AUTOSAR XML (schema 00045)
package /Comco
  client server interface CSI_NMWakupFlag
    operation NMWakupFlag: fire-and-forget=false, possible-error=[CSI_NMWakupFlag/E_NOT_OK, CSI_NMWakupFlag/E_OK]
      arg u_WakeupFlag: type=uint8_t, direction=OUT, server-argument-impl-policy=USE-ARGUMENT-TYPE
    error E_OK: error-code=0
    error E_NOT_OK: error-code=1
  client server interface CSI_nmCurrentState
    operation nmCurrentState: fire-and-forget=false, possible-error=[CSI_nmCurrentState/E_NOT_OK, CSI_nmCurrentState/E_OK]
      arg u_CurNmState: type=uint8_t, direction=OUT, server-argument-impl-policy=USE-ARGUMENT-TYPE
    error E_NOT_OK: error-code=1
    error E_OK: error-code=0
  client server interface CSI_nmPreviousState
    operation nmPreviousState: fire-and-forget=false, possible-error=[CSI_nmPreviousState/E_NOT_OK, CSI_nmPreviousState/E_OK]
      arg u_PreNmState: type=uint8_t, direction=OUT, server-argument-impl-policy=USE-ARGUMENT-TYPE
    error E_NOT_OK: error-code=1
    error E_OK: error-code=0
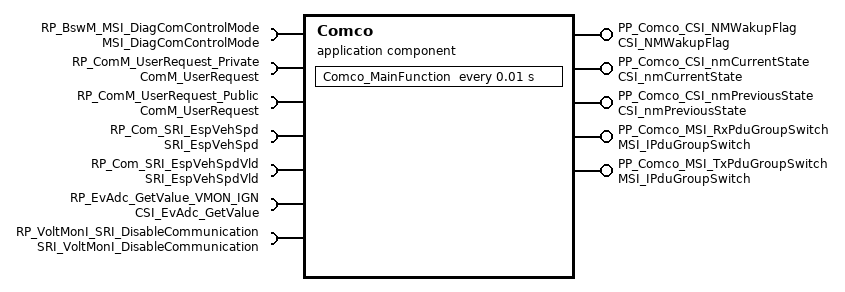
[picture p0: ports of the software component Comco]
  application sw component type Comco  # Communication Coordinator
    5 x provide port:
      PP_Comco_CSI_NMWakupFlag: provided-interface=CSI_NMWakupFlag
      PP_Comco_CSI_nmCurrentState: provided-interface=CSI_nmCurrentState
      PP_Comco_CSI_nmPreviousState: provided-interface=CSI_nmPreviousState
      PP_Comco_MSI_RxPduGroupSwitch: provided-interface=MSI_IPduGroupSwitch
      PP_Comco_MSI_TxPduGroupSwitch: provided-interface=MSI_IPduGroupSwitch
    7 x require port:
      RP_BswM_MSI_DiagComControlMode: required-interface=MSI_DiagComControlMode
      RP_ComM_UserRequest_Private: required-interface=ComM_UserRequest
      RP_ComM_UserRequest_Public: required-interface=ComM_UserRequest
      RP_Com_SRI_EspVehSpd: required-interface=SRI_EspVehSpd
      RP_Com_SRI_EspVehSpdVld: required-interface=SRI_EspVehSpdVld
      RP_EvAdc_GetValue_VMON_IGN: required-interface=CSI_EvAdc_GetValue
      RP_VoltMonI_SRI_DisableCommunication: required-interface=SRI_VoltMonI_DisableCommunication
    behavior Comco_IB: data-type-mapping=BswMModeMapping, handle-termination-and-restart=NO-SUPPORT
      timing event TimingEvent_Comco_MainFunction: start-on-event=Comco_MainFunction, period=0.01
      operation invoked event oie_PP_Comco_CSI_NMWakupFlag_NMWakupFlag: start-on-event=Comco_u_NMWakupFlag_Read, operation=PP_Comco_CSI_NMWakupFlag.NMWakupFlag
      operation invoked event oie_PP_Comco_CSI_nmCurrentState_nmCurrentState: start-on-event=Comco_u_nmCurrentState_Read, operation=PP_Comco_CSI_nmCurrentState.nmCurrentState
      operation invoked event oie_PP_Comco_CSI_nmPreviousState_nmPreviousState: start-on-event=Comco_u_nmPreviousState_Read, operation=PP_Comco_CSI_nmPreviousState.nmPreviousState
      4 x runnable:
        Comco_MainFunction: mode-access-point=RP_BswM_MSI_DiagComControlMode.proto_DcmCommunicationControl
          data-receive-point-by-arguments:
            access drparg_DE_EspVehSpd: accessed-variable=RP_Com_SRI_EspVehSpd.DE_EspVehSpd
            access drparg_DE_EspVehSpdVld: accessed-variable=RP_Com_SRI_EspVehSpdVld.DE_EspVehSpdVld
            access drparg_DE_VoltMonI_DisableCo: accessed-variable=RP_VoltMonI_SRI_DisableCommunication.DE_VoltMonI_DisableCommunication
          mode switch point msp_proto_MDG_IPduGroupSwitch_0: mode-group=PP_Comco_MSI_RxPduGroupSwitch.proto_MDG_IPduGroupSwitch
          mode switch point msp_proto_MDG_IPduGroupSwitch_1: mode-group=PP_Comco_MSI_TxPduGroupSwitch.proto_MDG_IPduGroupSwitch
          sync call scp_GetPhyValue: operation=RP_EvAdc_GetValue_VMON_IGN.GetPhyValue, timeout=0.0
          sync call scp_RequestComMode: operation=RP_ComM_UserRequest_Public.RequestComMode, timeout=0.0
          sync call scp_RequestComMode0: operation=RP_ComM_UserRequest_Private.RequestComMode, timeout=0.0
        Comco_u_NMWakupFlag_Read
        Comco_u_nmCurrentState_Read
        Comco_u_nmPreviousState_Read
  swc implementation Comco_Impl: programming-language=C, sw-version=1.0.0, vendor-id=0, behavior=Comco_IB
    code-descriptors:
      code comcoordinator: artifact-descriptors=autosar-engineering-object={short-label=SWSRC, category=SWSRC}
    resource consumption Resources
      memory section CODE: sw-addrmethod=CODE
      memory section CODE_LOCAL: options=coreLocal, sw-addrmethod=CODE_LOCAL
      memory section VAR_CLEARED_LOCAL: options=coreLocal, sw-addrmethod=VAR_CLEARED_LOCAL
